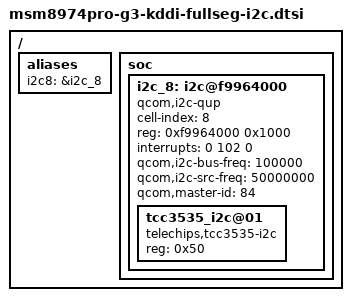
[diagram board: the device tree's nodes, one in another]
/*
 * Copyright (c) 2012, The Linux Foundation. All rights reserved.
 *
 * This program is free software; you can redistribute it and/or modify
 * it under the terms of the GNU General Public License version 2 and
 * only version 2 as published by the Free Software Foundation.
 *
 * This program is distributed in the hope that it will be useful,
 * but WITHOUT ANY WARRANTY; without even the implied warranty of
 * MERCHANTABILITY or FITNESS FOR A PARTICULAR PURPOSE.  See the
 * GNU General Public License for more details.
 */
/ {
	aliases {
		i2c8 = &i2c_8;
	};
	soc {
		i2c_8:i2c@f9964000{
			cell-index = <8>;
			compatible = "qcom,i2c-qup";
			#address-cells = <1>;
			#size-cells = <0>;

			reg-names = "qup_phys_addr";
			reg = <0xf9964000 0x1000>;
			interrupt-names = "qup_err_intr";
			interrupts = <0 102 0>;
/*Source clock frequency must be 50MHZ for MSM8974 V2 80-NE436-1_F_Configure_BLSPs_LA_MSM8974_MSM8x26_MDM9x25 */
			qcom,i2c-bus-freq = <100000>;
			qcom,i2c-src-freq = <50000000>;
			qcom,master-id = <84>;
		};
	};
};
&i2c_8 {
	tcc3535_i2c@01 {
		compatible = "telechips,tcc3535-i2c";
		reg = <0x50>;
	};
};

